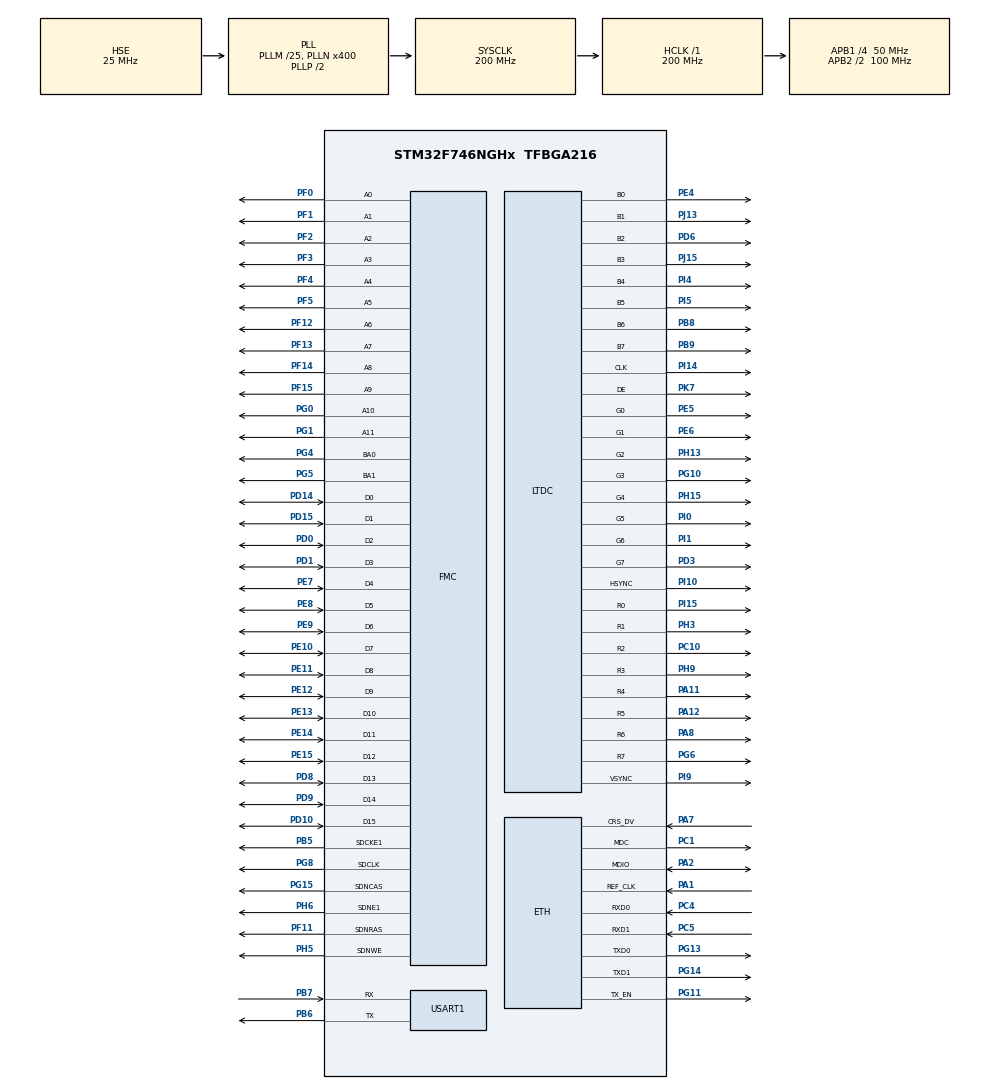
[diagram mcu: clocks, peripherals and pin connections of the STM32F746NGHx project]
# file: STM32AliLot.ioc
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CORTEX_M7.AccessPermission-Cortex_Memory_Protection_Unit_Region0_Settings=MPU_REGION_FULL_ACCESS
CORTEX_M7.AccessPermission-Cortex_Memory_Protection_Unit_Region1_Settings=MPU_REGION_FULL_ACCESS
CORTEX_M7.BaseAddress-Cortex_Memory_Protection_Unit_Region0_Settings=0x2004c000
CORTEX_M7.BaseAddress-Cortex_Memory_Protection_Unit_Region1_Settings=0x2004c000
CORTEX_M7.CPU_DCache=Enabled
CORTEX_M7.CPU_ICache=Enabled
CORTEX_M7.Enable-Cortex_Memory_Protection_Unit_Region0_Settings=MPU_REGION_ENABLE
CORTEX_M7.Enable-Cortex_Memory_Protection_Unit_Region1_Settings=MPU_REGION_ENABLE
CORTEX_M7.IsBufferable-Cortex_Memory_Protection_Unit_Region1_Settings=MPU_ACCESS_BUFFERABLE
CORTEX_M7.IsShareable-Cortex_Memory_Protection_Unit_Region0_Settings=MPU_ACCESS_SHAREABLE
CORTEX_M7.IsShareable-Cortex_Memory_Protection_Unit_Region1_Settings=MPU_ACCESS_SHAREABLE
CORTEX_M7.MPU_Control=MPU_PRIVILEGED_DEFAULT
CORTEX_M7.Size-Cortex_Memory_Protection_Unit_Region0_Settings=MPU_REGION_SIZE_16KB
CORTEX_M7.Size-Cortex_Memory_Protection_Unit_Region1_Settings=MPU_REGION_SIZE_256B
CORTEX_M7.TypeExtField-Cortex_Memory_Protection_Unit_Region0_Settings=MPU_TEX_LEVEL1
ETH.AutoNegotiation=ETH_AUTONEGOTIATION_ENABLE
ETH.MediaInterface=ETH_MEDIA_INTERFACE_RMII
ETH.PHY_Name_RMII=LAN8742A_PHY_ADDRESS
ETH.PhyAddress=0
FREERTOS.INCLUDE_xTaskAbortDelay=1
FREERTOS.Tasks01=defaultTask,0,1024,StartDefaultTask,Default,NULL,Dynamic,NULL,NULL
FREERTOS.configGENERATE_RUN_TIME_STATS=1
FREERTOS.configTOTAL_HEAP_SIZE=65536
LWIP.GATEWAY_ADDRESS=192.168.001.001
LWIP.IP_ADDRESS=192.168.001.010
LWIP.LWIP_DHCP=1
LWIP.LWIP_DNS=1
LWIP.LWIP_HTTPD=0
LWIP.LWIP_TFTP=0
LWIP.NETMASK_ADDRESS=255.255.255.000
LWIP.Version=v2.0.3_Cube
Mcu.Family=STM32F7
Mcu.Name=STM32F746NGHx
Mcu.Package=TFBGA216
NVIC.ETH_IRQn=true\:5\:0\:false\:false\:true\:true\:false\:true
NVIC.PriorityGroup=NVIC_PRIORITYGROUP_4
NVIC.TIM4_IRQn=true\:5\:0\:false\:false\:true\:true\:true\:true
NVIC.TIM6_DAC_IRQn=true\:0\:0\:false\:false\:true\:false\:false\:true
NVIC.TimeBase=TIM6_DAC_IRQn
NVIC.TimeBaseIP=TIM6
PA1.Mode=RMII
PA1.Signal=ETH_REF_CLK
PA11.Mode=RGB888
PA11.Signal=LTDC_R4
PA12.Mode=RGB888
PA12.Signal=LTDC_R5
PA13.Mode=Serial_Wire
PA13.Signal=SYS_JTMS-SWDIO
PA14.Mode=Serial_Wire
PA14.Signal=SYS_JTCK-SWCLK
PA2.Mode=RMII
PA2.Signal=ETH_MDIO
PA7.Mode=RMII
PA7.Signal=ETH_CRS_DV
PA8.Mode=RGB888
PA8.Signal=LTDC_R6
PB5.Mode=SdramChipSelect2_1
PB5.Signal=FMC_SDCKE1
PB6.Mode=Asynchronous
PB6.Signal=USART1_TX
PB7.Mode=Asynchronous
PB7.Signal=USART1_RX
PB8.Mode=RGB888
PB8.Signal=LTDC_B6
PB9.Mode=RGB888
PB9.Signal=LTDC_B7
PC1.Mode=RMII
PC1.Signal=ETH_MDC
PC10.Mode=RGB888
PC10.Signal=LTDC_R2
PC14/OSC32_IN.Mode=LSE-External-Oscillator
PC14/OSC32_IN.Signal=RCC_OSC32_IN
PC15/OSC32_OUT.Mode=LSE-External-Oscillator
PC15/OSC32_OUT.Signal=RCC_OSC32_OUT
PC4.Mode=RMII
PC4.Signal=ETH_RXD0
PC5.Mode=RMII
PC5.Signal=ETH_RXD1
PD0.Signal=FMC_D2_DA2
PD1.Signal=FMC_D3_DA3
PD10.Signal=FMC_D15_DA15
PD14.Signal=FMC_D0_DA0
PD15.Signal=FMC_D1_DA1
PD3.Mode=RGB888
PD3.Signal=LTDC_G7
PD6.Mode=RGB888
PD6.Signal=LTDC_B2
PD8.Signal=FMC_D13_DA13
PD9.Signal=FMC_D14_DA14
PE10.Signal=FMC_D7_DA7
PE11.Signal=FMC_D8_DA8
PE12.Signal=FMC_D9_DA9
PE13.Signal=FMC_D10_DA10
PE14.Signal=FMC_D11_DA11
PE15.Signal=FMC_D12_DA12
PE4.Mode=RGB888
PE4.Signal=LTDC_B0
PE5.Mode=RGB888
PE5.Signal=LTDC_G0
PE6.Mode=RGB888
PE6.Signal=LTDC_G1
PE7.Signal=FMC_D4_DA4
PE8.Signal=FMC_D5_DA5
PE9.Signal=FMC_D6_DA6
PF0.Signal=FMC_A0
PF1.Signal=FMC_A1
PF11.Signal=FMC_SDNRAS
PF12.Signal=FMC_A6
PF13.Signal=FMC_A7
PF14.Signal=FMC_A8
PF15.Signal=FMC_A9
PF2.Signal=FMC_A2
PF3.Signal=FMC_A3
PF4.Signal=FMC_A4
PF5.Signal=FMC_A5
PG0.Signal=FMC_A10
PG1.Signal=FMC_A11
PG10.Mode=RGB888
PG10.Signal=LTDC_G3
PG11.Mode=RMII
PG11.Signal=ETH_TX_EN
PG13.Mode=RMII
PG13.Signal=ETH_TXD0
PG14.Mode=RMII
PG14.Signal=ETH_TXD1
PG15.Signal=FMC_SDNCAS
PG4.Signal=FMC_A14_BA0
PG5.Signal=FMC_A15_BA1
PG6.Mode=RGB888
PG6.Signal=LTDC_R7
PG8.Signal=FMC_SDCLK
PH0/OSC_IN.Mode=HSE-External-Oscillator
PH0/OSC_IN.Signal=RCC_OSC_IN
PH1/OSC_OUT.Mode=HSE-External-Oscillator
PH1/OSC_OUT.Signal=RCC_OSC_OUT
PH13.Mode=RGB888
PH13.Signal=LTDC_G2
PH15.Mode=RGB888
PH15.Signal=LTDC_G4
PH3.Mode=RGB888
PH3.Signal=LTDC_R1
PH5.Signal=FMC_SDNWE
PH6.Mode=SdramChipSelect2_1
PH6.Signal=FMC_SDNE1
PH9.Mode=RGB888
PH9.Signal=LTDC_R3
PI0.Mode=RGB888
PI0.Signal=LTDC_G5
PI1.Mode=RGB888
PI1.Signal=LTDC_G6
PI10.Mode=RGB888
PI10.Signal=LTDC_HSYNC
PI14.Mode=RGB888
PI14.Signal=LTDC_CLK
PI15.Mode=RGB888
PI15.Signal=LTDC_R0
PI4.Mode=RGB888
PI4.Signal=LTDC_B4
PI5.Mode=RGB888
PI5.Signal=LTDC_B5
PI9.Mode=RGB888
PI9.Signal=LTDC_VSYNC
PJ13.Mode=RGB888
PJ13.Signal=LTDC_B1
PJ15.Mode=RGB888
PJ15.Signal=LTDC_B3
PK7.Mode=RGB888
PK7.Signal=LTDC_DE
ProjectManager.HeapSize=0x200
ProjectManager.StackSize=0x400
ProjectManager.TargetToolchain=STM32CubeIDE
RCC.AHBFreq_Value=200000000
RCC.APB1CLKDivider=RCC_HCLK_DIV4
RCC.APB1Freq_Value=50000000
RCC.APB1TimFreq_Value=100000000
RCC.APB2CLKDivider=RCC_HCLK_DIV2
RCC.APB2Freq_Value=100000000
RCC.APB2TimFreq_Value=200000000
RCC.CortexFreq_Value=200000000
RCC.HCLKFreq_Value=200000000
RCC.HSE_VALUE=25000000
RCC.HSI_VALUE=16000000
RCC.PLL48CLockSelection=RCC_CLK48SOURCE_PLLSAIP
RCC.PLLI2SN=100
RCC.PLLM=25
RCC.PLLN=400
RCC.PLLQ=9
RCC.PLLSAIN=384
RCC.PLLSAIP=RCC_PLLSAIP_DIV8
RCC.PLLSAIR=5
RCC.PLLSAIRDiv=RCC_PLLSAIDIVR_8
RCC.PLLSourceVirtual=RCC_PLLSOURCE_HSE
RCC.RCC_MCO1Source=RCC_MCO1SOURCE_PLLCLK
RCC.RCC_MCO2Source=RCC_MCO2SOURCE_PLLCLK
RCC.RCC_MCODiv1=RCC_MCODIV_4
RCC.RCC_MCODiv2=RCC_MCODIV_4
RCC.RCC_TIM_PRescaler_Selection=RCC_TIMPRES_DESACTIVATED
RCC.SDMMCClockSelection=RCC_SDMMC1CLKSOURCE_CLK48
RCC.SYSCLKFreq_VALUE=200000000
RCC.SYSCLKSource=RCC_SYSCLKSOURCE_PLLCLK
RCC.USBFreq_Value=48000000
RCC.VCOOutputFreq_Value=400000000
SH.FMC_A0.0=FMC_A0,12b-sda1
SH.FMC_A1.0=FMC_A1,12b-sda1
SH.FMC_A10.0=FMC_A10,12b-sda1
SH.FMC_A11.0=FMC_A11,12b-sda1
SH.FMC_A14_BA0.0=FMC_BA0,FourSdramBanks1
SH.FMC_A15_BA1.0=FMC_BA1,FourSdramBanks1
SH.FMC_A2.0=FMC_A2,12b-sda1
SH.FMC_A3.0=FMC_A3,12b-sda1
SH.FMC_A4.0=FMC_A4,12b-sda1
SH.FMC_A5.0=FMC_A5,12b-sda1
SH.FMC_A6.0=FMC_A6,12b-sda1
SH.FMC_A7.0=FMC_A7,12b-sda1
SH.FMC_A8.0=FMC_A8,12b-sda1
SH.FMC_A9.0=FMC_A9,12b-sda1
SH.FMC_D0_DA0.0=FMC_D0,sd-16b-d1
SH.FMC_D10_DA10.0=FMC_D10,sd-16b-d1
SH.FMC_D11_DA11.0=FMC_D11,sd-16b-d1
SH.FMC_D12_DA12.0=FMC_D12,sd-16b-d1
SH.FMC_D13_DA13.0=FMC_D13,sd-16b-d1
SH.FMC_D14_DA14.0=FMC_D14,sd-16b-d1
SH.FMC_D15_DA15.0=FMC_D15,sd-16b-d1
SH.FMC_D1_DA1.0=FMC_D1,sd-16b-d1
SH.FMC_D2_DA2.0=FMC_D2,sd-16b-d1
SH.FMC_D3_DA3.0=FMC_D3,sd-16b-d1
SH.FMC_D4_DA4.0=FMC_D4,sd-16b-d1
SH.FMC_D5_DA5.0=FMC_D5,sd-16b-d1
SH.FMC_D6_DA6.0=FMC_D6,sd-16b-d1
SH.FMC_D7_DA7.0=FMC_D7,sd-16b-d1
SH.FMC_D8_DA8.0=FMC_D8,sd-16b-d1
SH.FMC_D9_DA9.0=FMC_D9,sd-16b-d1
SH.FMC_SDCLK.0=FMC_SDCLK,12b-sda1
SH.FMC_SDNCAS.0=FMC_SDNCAS,12b-sda1
SH.FMC_SDNRAS.0=FMC_SDNRAS,12b-sda1
SH.FMC_SDNWE.0=FMC_SDNWE,12b-sda1
TIM4.AutoReloadPreload=TIM_AUTORELOAD_PRELOAD_ENABLE
TIM4.Period=1000-1
TIM4.Prescaler=200-1
USART1.VirtualMode-Asynchronous=VM_ASYNC
VP_CRC_VS_CRC.Mode=CRC_Activate
VP_DMA2D_VS_DMA2D.Mode=DMA2D_Activate
VP_FREERTOS_VS_CMSIS_V1.Mode=CMSIS_V1
VP_LWIP_VS_Enabled.Mode=Enabled
VP_RNG_VS_RNG.Mode=RNG_Activate
VP_SYS_VS_tim6.Mode=TIM6
VP_TIM4_VS_ClockSourceINT.Mode=Internal
board=STM32F746G-DISCO

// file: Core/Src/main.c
/* USER CODE BEGIN Header */
/**
  ******************************************************************************
  * @file           : main.c
  * @brief          : Main program body
  ******************************************************************************
  * @attention
  *
  * <h2><center>&copy; Copyright (c) 2020 STMicroelectronics.
  * All rights reserved.</center></h2>
  *
  * This software component is licensed by ST under Ultimate Liberty license
  * SLA0044, the "License"; You may not use this file except in compliance with
  * the License. You may obtain a copy of the License at:
  *                             www.st.com/SLA0044
  *
  ******************************************************************************
  */
/* USER CODE END Header */

#include "main.h"
#include "cmsis_os.h"
#include "crc.h"
#include "dma2d.h"
#include "ltdc.h"
#include "lwip.h"
#include "rng.h"
#include "tim.h"
#include "usart.h"
#include "gpio.h"
#include "fmc.h"

void SystemClock_Config(void);
static void MPU_Config(void);
void MX_FREERTOS_Init(void);

int main(void)
{

  /* MPU Configuration--------------------------------------------------------*/
  MPU_Config();

  /* Enable I-Cache---------------------------------------------------------*/
  SCB_EnableICache();

  /* Enable D-Cache---------------------------------------------------------*/
  SCB_EnableDCache();

  /* MCU Configuration--------------------------------------------------------*/

  /* Reset of all peripherals, Initializes the Flash interface and the Systick. */
  HAL_Init();

  /* Configure the system clock */
  SystemClock_Config();

  /* Initialize all configured peripherals */
  MX_GPIO_Init();
  MX_CRC_Init();
  MX_USART1_UART_Init();
  MX_LWIP_Init();
  MX_LTDC_Init();
  MX_DMA2D_Init();
  MX_FMC_Init();
  MX_TIM4_Init();
  MX_RNG_Init();

  /* Call init function for freertos objects (in freertos.c) */
  MX_FREERTOS_Init();

  /* Start scheduler */
  osKernelStart();

  /* We should never get here as control is now taken by the scheduler */

  /* Infinite loop */
  while (1)
  {

  }
}

void SystemClock_Config(void)
{
  RCC_OscInitTypeDef RCC_OscInitStruct = {0};
  RCC_ClkInitTypeDef RCC_ClkInitStruct = {0};
  RCC_PeriphCLKInitTypeDef PeriphClkInitStruct = {0};

  /** Configure LSE Drive Capability
  */
  HAL_PWR_EnableBkUpAccess();
  /** Configure the main internal regulator output voltage
  */
  __HAL_RCC_PWR_CLK_ENABLE();
  __HAL_PWR_VOLTAGESCALING_CONFIG(PWR_REGULATOR_VOLTAGE_SCALE1);
  /** Initializes the CPU, AHB and APB busses clocks
  */
  RCC_OscInitStruct.OscillatorType = RCC_OSCILLATORTYPE_HSE;
  RCC_OscInitStruct.HSEState = RCC_HSE_ON;
  RCC_OscInitStruct.PLL.PLLState = RCC_PLL_ON;
  RCC_OscInitStruct.PLL.PLLSource = RCC_PLLSOURCE_HSE;
  RCC_OscInitStruct.PLL.PLLM = 25;
  RCC_OscInitStruct.PLL.PLLN = 400;
  RCC_OscInitStruct.PLL.PLLP = RCC_PLLP_DIV2;
  RCC_OscInitStruct.PLL.PLLQ = 9;
  if (HAL_RCC_OscConfig(&RCC_OscInitStruct) != HAL_OK)
  {
    Error_Handler();
  }
  /** Activate the Over-Drive mode
  */
  if (HAL_PWREx_EnableOverDrive() != HAL_OK)
  {
    Error_Handler();
  }
  /** Initializes the CPU, AHB and APB busses clocks
  */
  RCC_ClkInitStruct.ClockType = RCC_CLOCKTYPE_HCLK|RCC_CLOCKTYPE_SYSCLK
                              |RCC_CLOCKTYPE_PCLK1|RCC_CLOCKTYPE_PCLK2;
  RCC_ClkInitStruct.SYSCLKSource = RCC_SYSCLKSOURCE_PLLCLK;
  RCC_ClkInitStruct.AHBCLKDivider = RCC_SYSCLK_DIV1;
  RCC_ClkInitStruct.APB1CLKDivider = RCC_HCLK_DIV4;
  RCC_ClkInitStruct.APB2CLKDivider = RCC_HCLK_DIV2;

  if (HAL_RCC_ClockConfig(&RCC_ClkInitStruct, FLASH_LATENCY_6) != HAL_OK)
  {
    Error_Handler();
  }
  PeriphClkInitStruct.PeriphClockSelection = RCC_PERIPHCLK_LTDC|RCC_PERIPHCLK_USART1
                              |RCC_PERIPHCLK_CLK48;
  PeriphClkInitStruct.PLLSAI.PLLSAIN = 384;
  PeriphClkInitStruct.PLLSAI.PLLSAIR = 5;
  PeriphClkInitStruct.PLLSAI.PLLSAIQ = 2;
  PeriphClkInitStruct.PLLSAI.PLLSAIP = RCC_PLLSAIP_DIV8;
  PeriphClkInitStruct.PLLSAIDivQ = 1;
  PeriphClkInitStruct.PLLSAIDivR = RCC_PLLSAIDIVR_8;
  PeriphClkInitStruct.Usart1ClockSelection = RCC_USART1CLKSOURCE_PCLK2;
  PeriphClkInitStruct.Clk48ClockSelection = RCC_CLK48SOURCE_PLLSAIP;
  if (HAL_RCCEx_PeriphCLKConfig(&PeriphClkInitStruct) != HAL_OK)
  {
    Error_Handler();
  }
}

/* MPU Configuration */

void MPU_Config(void)
{
  MPU_Region_InitTypeDef MPU_InitStruct = {0};

  /* Disables the MPU */
  HAL_MPU_Disable();
  /** Initializes and configures the Region and the memory to be protected
  */
  MPU_InitStruct.Enable = MPU_REGION_ENABLE;
  MPU_InitStruct.Number = MPU_REGION_NUMBER0;
  MPU_InitStruct.BaseAddress = 0x2004c000;
  MPU_InitStruct.Size = MPU_REGION_SIZE_16KB;
  MPU_InitStruct.SubRegionDisable = 0x0;
  MPU_InitStruct.TypeExtField = MPU_TEX_LEVEL1;
  MPU_InitStruct.AccessPermission = MPU_REGION_FULL_ACCESS;
  MPU_InitStruct.DisableExec = MPU_INSTRUCTION_ACCESS_ENABLE;
  MPU_InitStruct.IsShareable = MPU_ACCESS_SHAREABLE;
  MPU_InitStruct.IsCacheable = MPU_ACCESS_NOT_CACHEABLE;
  MPU_InitStruct.IsBufferable = MPU_ACCESS_NOT_BUFFERABLE;

  HAL_MPU_ConfigRegion(&MPU_InitStruct);
  /** Initializes and configures the Region and the memory to be protected
  */
  MPU_InitStruct.Enable = MPU_REGION_ENABLE;
  MPU_InitStruct.Number = MPU_REGION_NUMBER1;
  MPU_InitStruct.BaseAddress = 0x2004c000;
  MPU_InitStruct.Size = MPU_REGION_SIZE_256B;
  MPU_InitStruct.SubRegionDisable = 0x0;
  MPU_InitStruct.TypeExtField = MPU_TEX_LEVEL0;
  MPU_InitStruct.AccessPermission = MPU_REGION_FULL_ACCESS;
  MPU_InitStruct.DisableExec = MPU_INSTRUCTION_ACCESS_ENABLE;
  MPU_InitStruct.IsShareable = MPU_ACCESS_SHAREABLE;
  MPU_InitStruct.IsCacheable = MPU_ACCESS_NOT_CACHEABLE;
  MPU_InitStruct.IsBufferable = MPU_ACCESS_BUFFERABLE;

  HAL_MPU_ConfigRegion(&MPU_InitStruct);
  /* Enables the MPU */
  HAL_MPU_Enable(MPU_PRIVILEGED_DEFAULT);

}
void HAL_TIM_PeriodElapsedCallback(TIM_HandleTypeDef *htim)
{
  if (htim->Instance == TIM6) {
    HAL_IncTick();
  }
}

void Error_Handler(void)
{
}

/************************ (C) COPYRIGHT STMicroelectronics *****END OF FILE****/

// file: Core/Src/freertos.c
/* USER CODE BEGIN Header */
/**
 ******************************************************************************
 * File Name          : freertos.c
 * Description        : Code for freertos applications
 ******************************************************************************
 * @attention
 *
 * <h2><center>&copy; Copyright (c) 2020 STMicroelectronics.
 * All rights reserved.</center></h2>
 *
 * This software component is licensed by ST under Ultimate Liberty license
 * SLA0044, the "License"; You may not use this file except in compliance with
 * the License. You may obtain a copy of the License at:
 *                             www.st.com/SLA0044
 *
 ******************************************************************************
 */
/* USER CODE END Header */

#include "FreeRTOS.h"
#include "task.h"
#include "main.h"
#include "cmsis_os.h"

/* USER CODE BEGIN Includes */
#include "stm32746g_discovery.h"
#include "stm32746g_discovery_lcd.h"
#include "lcd_log.h"
#include "app_ethernet.h"
#include "mqttclient.h"
#include "tim.h"
/* USER CODE END Includes */

/* USER CODE BEGIN Variables */
extern uint32_t RUN_Time;
extern struct netif gnetif;
osThreadId AliCloudTaskHandle;
/* USER CODE END Variables */
osThreadId defaultTaskHandle;

/* USER CODE BEGIN FunctionPrototypes */
static void BSP_Config(void);
/* USER CODE END FunctionPrototypes */

void StartDefaultTask(void const *argument);

extern void MX_LWIP_Init(void);
void MX_FREERTOS_Init(void); /* (MISRA C 2004 rule 8.1) */

/* GetIdleTaskMemory prototype (linked to static allocation support) */
void vApplicationGetIdleTaskMemory(StaticTask_t **ppxIdleTaskTCBBuffer,
		StackType_t **ppxIdleTaskStackBuffer, uint32_t *pulIdleTaskStackSize);

/* Hook prototypes */
void configureTimerForRunTimeStats(void);
unsigned long getRunTimeCounterValue(void);

/* USER CODE BEGIN 1 */
/* Functions needed when configGENERATE_RUN_TIME_STATS is on */
__weak void configureTimerForRunTimeStats(void)
{
	RUN_Time = 0;
	MX_TIM4_Init();
	HAL_TIM_Base_Start_IT(&htim4);
}

__weak unsigned long getRunTimeCounterValue(void)
{
	return RUN_Time;
}
/* USER CODE END 1 */

/* USER CODE BEGIN GET_IDLE_TASK_MEMORY */
static StaticTask_t xIdleTaskTCBBuffer;
static StackType_t xIdleStack[configMINIMAL_STACK_SIZE];

void vApplicationGetIdleTaskMemory(StaticTask_t **ppxIdleTaskTCBBuffer,
		StackType_t **ppxIdleTaskStackBuffer, uint32_t *pulIdleTaskStackSize)
{
	*ppxIdleTaskTCBBuffer = &xIdleTaskTCBBuffer;
	*ppxIdleTaskStackBuffer = &xIdleStack[0];
	*pulIdleTaskStackSize = configMINIMAL_STACK_SIZE;
	/* place for user code */
}
/* USER CODE END GET_IDLE_TASK_MEMORY */

void MX_FREERTOS_Init(void)
{

	/* Create the thread(s) */
	/* definition and creation of defaultTask */
	osThreadDef(defaultTask, StartDefaultTask, osPriorityNormal, 0, 1024);
	defaultTaskHandle = osThreadCreate(osThread(defaultTask), NULL);

}

void StartDefaultTask(void const *argument)
{
	/* USER CODE BEGIN StartDefaultTask */
	BSP_Config();
	User_notification(&gnetif);

#ifdef USE_DHCP
	osThreadDef(DHCP, DHCP_thread, osPriorityAboveNormal, 0, 256);
	osThreadCreate(osThread(DHCP), &gnetif);
	while (DHCP_state != DHCP_ADDRESS_ASSIGNED )
		;
#endif
	osThreadDef(AliCloud, AliCloud_thread, osPriorityNormal, 0, 10240);
	AliCloudTaskHandle = osThreadCreate(osThread(AliCloud), NULL);
	osThreadTerminate(NULL);
	/* Infinite loop */
	for (;;)
	{
		osDelay(1);
	}
	/* USER CODE END StartDefaultTask */
}

/* USER CODE BEGIN Application */
/**
 * @brief  Initializes the STM327546G-Discovery's LCD  resources.
 * @param  None
 * @retval None
 */
static void BSP_Config(void)
{
	/* Initialize the LCD */
	BSP_LCD_Init();

	/* Initialize the LCD Layers */
	BSP_LCD_LayerDefaultInit(1, LCD_FB_START_ADDRESS);

	/* Set LCD Foreground Layer  */
	BSP_LCD_SelectLayer(1);

	BSP_LCD_SetFont(&LCD_DEFAULT_FONT);

	/* Initialize LCD Log module */
	LCD_LOG_Init();

	/* Show Header and Footer texts */
	LCD_LOG_SetHeader((uint8_t*) "Webserver Application Netconn API");
	LCD_LOG_SetFooter((uint8_t*) "STM32746G-DISCO board");

	LCD_UsrLog((char* )"  State: Ethernet Initialization ...\n");
}
/* USER CODE END Application */

/************************ (C) COPYRIGHT STMicroelectronics *****END OF FILE****/
